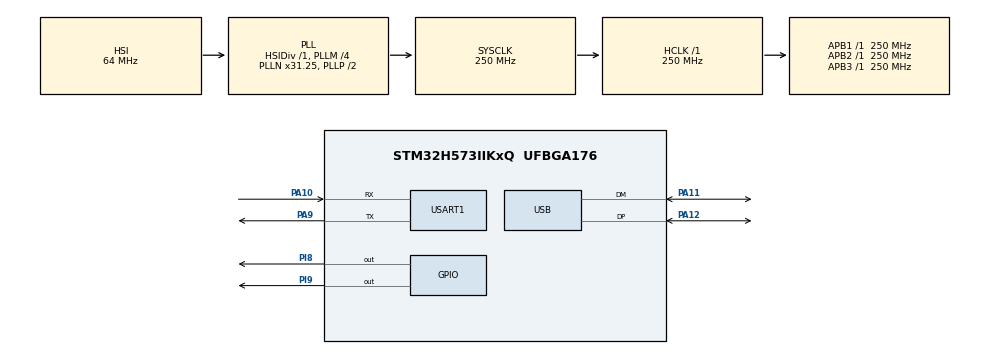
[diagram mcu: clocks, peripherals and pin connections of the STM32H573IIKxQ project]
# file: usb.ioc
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BOOTPATH.BootPathName=LEGACY
BOOTPATH.UserSelectedBootPath=LEGACY
CORTEX_M33_NS.userName=CORTEX_M33
Mcu.Family=STM32H5
Mcu.Name=STM32H573IIKxQ
Mcu.Package=UFBGA176
NVIC.PriorityGroup=NVIC_PRIORITYGROUP_4
NVIC.TIM6_IRQn=true\:15\:0\:false\:false\:true\:false\:false\:true\:true
NVIC.TimeBase=TIM6_IRQn
NVIC.TimeBaseIP=TIM6
NVIC.USB_DRD_FS_IRQn=true\:0\:0\:false\:false\:true\:false\:true\:true\:true
PA10.Mode=Asynchronous
PA10.Signal=USART1_RX
PA11.Mode=Device
PA11.Signal=USB_DM
PA12.Mode=Device
PA12.Signal=USB_DP
PA9.Mode=Asynchronous
PA9.Signal=USART1_TX
PH0-OSC_IN(PH0).Mode=HSE-External-Oscillator
PH0-OSC_IN(PH0).Signal=RCC_OSC_IN
PH1-OSC_OUT(PH1).Mode=HSE-External-Oscillator
PH1-OSC_OUT(PH1).Signal=RCC_OSC_OUT
PI8.Signal=GPIO_Output
PI9.Signal=GPIO_Output
ProjectManager.HeapSize=0x200
ProjectManager.StackSize=0x400
ProjectManager.TargetToolchain=STM32CubeIDE
RCC.ADCFreq_Value=250000000
RCC.AHBFreq_Value=250000000
RCC.APB1Freq_Value=250000000
RCC.APB1TimFreq_Value=250000000
RCC.APB2Freq_Value=250000000
RCC.APB2TimFreq_Value=250000000
RCC.APB3Freq_Value=250000000
RCC.CSI_VALUE=4000000
RCC.CortexFreq_Value=250000000
RCC.DATA_CACHE_ENABLE=1
RCC.EPOD_VALUE=64000000
RCC.HCLKFreq_Value=250000000
RCC.HSE_VALUE=25000000
RCC.HSI48_VALUE=48000000
RCC.HSIDiv=RCC_HSI_DIV1
RCC.HSI_VALUE=64000000
RCC.INSTRUCTION_CACHE_ENABLE=1
RCC.LSE_VALUE=32768
RCC.LSIRC_VALUE=32000
RCC.PLL1Q=20
RCC.PLL2FRACN=0
RCC.PLL3FRACN=0
RCC.PLLFRACN=2048
RCC.PLLM=4
RCC.PLLN=31
RCC.PLLSourceVirtual=RCC_PLL1_SOURCE_HSI
RCC.PREFETCH_ENABLE=1
RCC.PWREXT_OverDrive=PWREXT_OverDrive_DESACTIVATED
RCC.SYSCLKFreq_VALUE=250000000
RCC.SYSCLKSource=RCC_SYSCLKSOURCE_PLLCLK
RCC.USBFreq_Value=48000000
RCC.VCOOutputFreq_Value=500000000
USART1.VirtualMode-Asynchronous=VM_ASYNC
USB.VirtualMode=Device_Only
USBX.BSP.number=1
USBX.Core_System=1
USBX.USBD_CDCACM_EPINCMD_ADDR=2
USBX.USBD_CDCACM_EPIN_ADDR=1
USBX.USBX_DEVICE_SYS_SIZE=6*1024
USBX.UX_DEVICE_APP_MEM_POOL_SIZE=11*1024
USBX.UX_DEVICE_CDC_ACM=1
USBX.UX_DEVICE_CLASS_CDC_ACM_TRANSMISSION_DISABLE=1
USBX.UX_DEVICE_CLASS_CDC_ACM_WRITE_AUTO_ZLP=1
USBX.UX_Device_Controller=1
USBX.UX_Device_CoreStack=1
USBX.UX_SLAVE_REQUEST_DATA_MAX_LENGTH=512
USBX0.BSP.STBoard=false
USBX0.BSP.api=Unknown
USBX0.BSP.instance=USB
USBX0.BSP.ip=USB
USBX0.BSP.mode=Device_Only
USBX0.BSP.name=USB_Device
USBX0.BSP.solution=USB
VP_BOOTPATH_VS_BOOTPATH.Mode=BP_Activate
VP_CORTEX_M33_NS_VS_Hclk.Mode=Hclk_Mode
VP_ICACHE_VS_ICACHE.Mode=DirectMappedCache
VP_MEMORYMAP_VS_MEMORYMAP.Mode=CurAppReg
VP_PWR_VS_LPOM.Mode=PowerOptimisation
VP_PWR_VS_SECSignals.Mode=Security/Privilege
VP_SYS_VS_tim6.Mode=TIM6
VP_THREADX_VS_RTOSJjThreadXJjCoreJjDefault.Mode=Core_Default
VP_USBX_Core_System.Mode=Core_System
VP_USBX_UX\ Device\ CDC\ ACM\ Class_FS.Mode=UX_Device_class_CDC_ACM_FS
VP_USBX_UX\ Device\ Controller_FS.Mode=UX_Device_Controller_FS
VP_USBX_UX\ Device\ CoreStack_FS.Mode=UX_Device_CoreStack_FS
board=custom

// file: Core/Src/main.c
/* USER CODE BEGIN Header */
/**
  ******************************************************************************
  * @file           : main.c
  * @brief          : Main program body
  ******************************************************************************
  * @attention
  *
  * Copyright (c) 2025 STMicroelectronics.
  * All rights reserved.
  *
  * This software is licensed under terms that can be found in the LICENSE file
  * in the root directory of this software component.
  * If no LICENSE file comes with this software, it is provided AS-IS.
  *
  ******************************************************************************
  */
/* USER CODE END Header */
#include "app_threadx.h"
#include "main.h"
#include "icache.h"
#include "usart.h"
#include "usb.h"
#include "gpio.h"

/* USER CODE BEGIN Includes */
#include "ux_device_cdc_acm.h"
#include <stdio.h>
/* USER CODE END Includes */

/* USER CODE BEGIN PV */
extern UX_SLAVE_CLASS_CDC_ACM *cdc_acm_instance;
/* USER CODE END PV */

void SystemClock_Config(void);

/* USER CODE BEGIN 0 */
int __io_putchar(int ch)
{
    HAL_UART_Transmit(&huart1, (uint8_t *)&ch, 1, HAL_MAX_DELAY);
    return ch;
}
/* USER CODE END 0 */

int main(void)
{

  /* MCU Configuration--------------------------------------------------------*/

  /* Reset of all peripherals, Initializes the Flash interface and the Systick. */
  HAL_Init();

  /* Configure the system clock */
  SystemClock_Config();

  /* Initialize all configured peripherals */
  MX_GPIO_Init();
  MX_ICACHE_Init();
  MX_USART1_UART_Init();

  MX_ThreadX_Init();

  /* We should never get here as control is now taken by the scheduler */

  /* Infinite loop */
  while (1)
  {

  }
}

void SystemClock_Config(void)
{
  RCC_OscInitTypeDef RCC_OscInitStruct = {0};
  RCC_ClkInitTypeDef RCC_ClkInitStruct = {0};

  /** Configure the main internal regulator output voltage
  */
  __HAL_PWR_VOLTAGESCALING_CONFIG(PWR_REGULATOR_VOLTAGE_SCALE0);

  while(!__HAL_PWR_GET_FLAG(PWR_FLAG_VOSRDY)) {}

  /** Initializes the RCC Oscillators according to the specified parameters
  * in the RCC_OscInitTypeDef structure.
  */
  RCC_OscInitStruct.OscillatorType = RCC_OSCILLATORTYPE_HSI48|RCC_OSCILLATORTYPE_HSI;
  RCC_OscInitStruct.HSIState = RCC_HSI_ON;
  RCC_OscInitStruct.HSIDiv = RCC_HSI_DIV1;
  RCC_OscInitStruct.HSICalibrationValue = RCC_HSICALIBRATION_DEFAULT;
  RCC_OscInitStruct.HSI48State = RCC_HSI48_ON;
  RCC_OscInitStruct.PLL.PLLState = RCC_PLL_ON;
  RCC_OscInitStruct.PLL.PLLSource = RCC_PLL1_SOURCE_HSI;
  RCC_OscInitStruct.PLL.PLLM = 4;
  RCC_OscInitStruct.PLL.PLLN = 31;
  RCC_OscInitStruct.PLL.PLLP = 2;
  RCC_OscInitStruct.PLL.PLLQ = 20;
  RCC_OscInitStruct.PLL.PLLR = 2;
  RCC_OscInitStruct.PLL.PLLRGE = RCC_PLL1_VCIRANGE_3;
  RCC_OscInitStruct.PLL.PLLVCOSEL = RCC_PLL1_VCORANGE_WIDE;
  RCC_OscInitStruct.PLL.PLLFRACN = 2048;
  if (HAL_RCC_OscConfig(&RCC_OscInitStruct) != HAL_OK)
  {
    Error_Handler();
  }

  /** Initializes the CPU, AHB and APB buses clocks
  */
  RCC_ClkInitStruct.ClockType = RCC_CLOCKTYPE_HCLK|RCC_CLOCKTYPE_SYSCLK
                              |RCC_CLOCKTYPE_PCLK1|RCC_CLOCKTYPE_PCLK2
                              |RCC_CLOCKTYPE_PCLK3;
  RCC_ClkInitStruct.SYSCLKSource = RCC_SYSCLKSOURCE_PLLCLK;
  RCC_ClkInitStruct.AHBCLKDivider = RCC_SYSCLK_DIV1;
  RCC_ClkInitStruct.APB1CLKDivider = RCC_HCLK_DIV1;
  RCC_ClkInitStruct.APB2CLKDivider = RCC_HCLK_DIV1;
  RCC_ClkInitStruct.APB3CLKDivider = RCC_HCLK_DIV1;

  if (HAL_RCC_ClockConfig(&RCC_ClkInitStruct, FLASH_LATENCY_5) != HAL_OK)
  {
    Error_Handler();
  }

  /** Configure the programming delay
  */
  __HAL_FLASH_SET_PROGRAM_DELAY(FLASH_PROGRAMMING_DELAY_2);
}

void HAL_TIM_PeriodElapsedCallback(TIM_HandleTypeDef *htim)
{
  if (htim->Instance == TIM6)
  {
    HAL_IncTick();
  }
}

void Error_Handler(void)
{
  __disable_irq();
  while (1)
  {
  }
}
